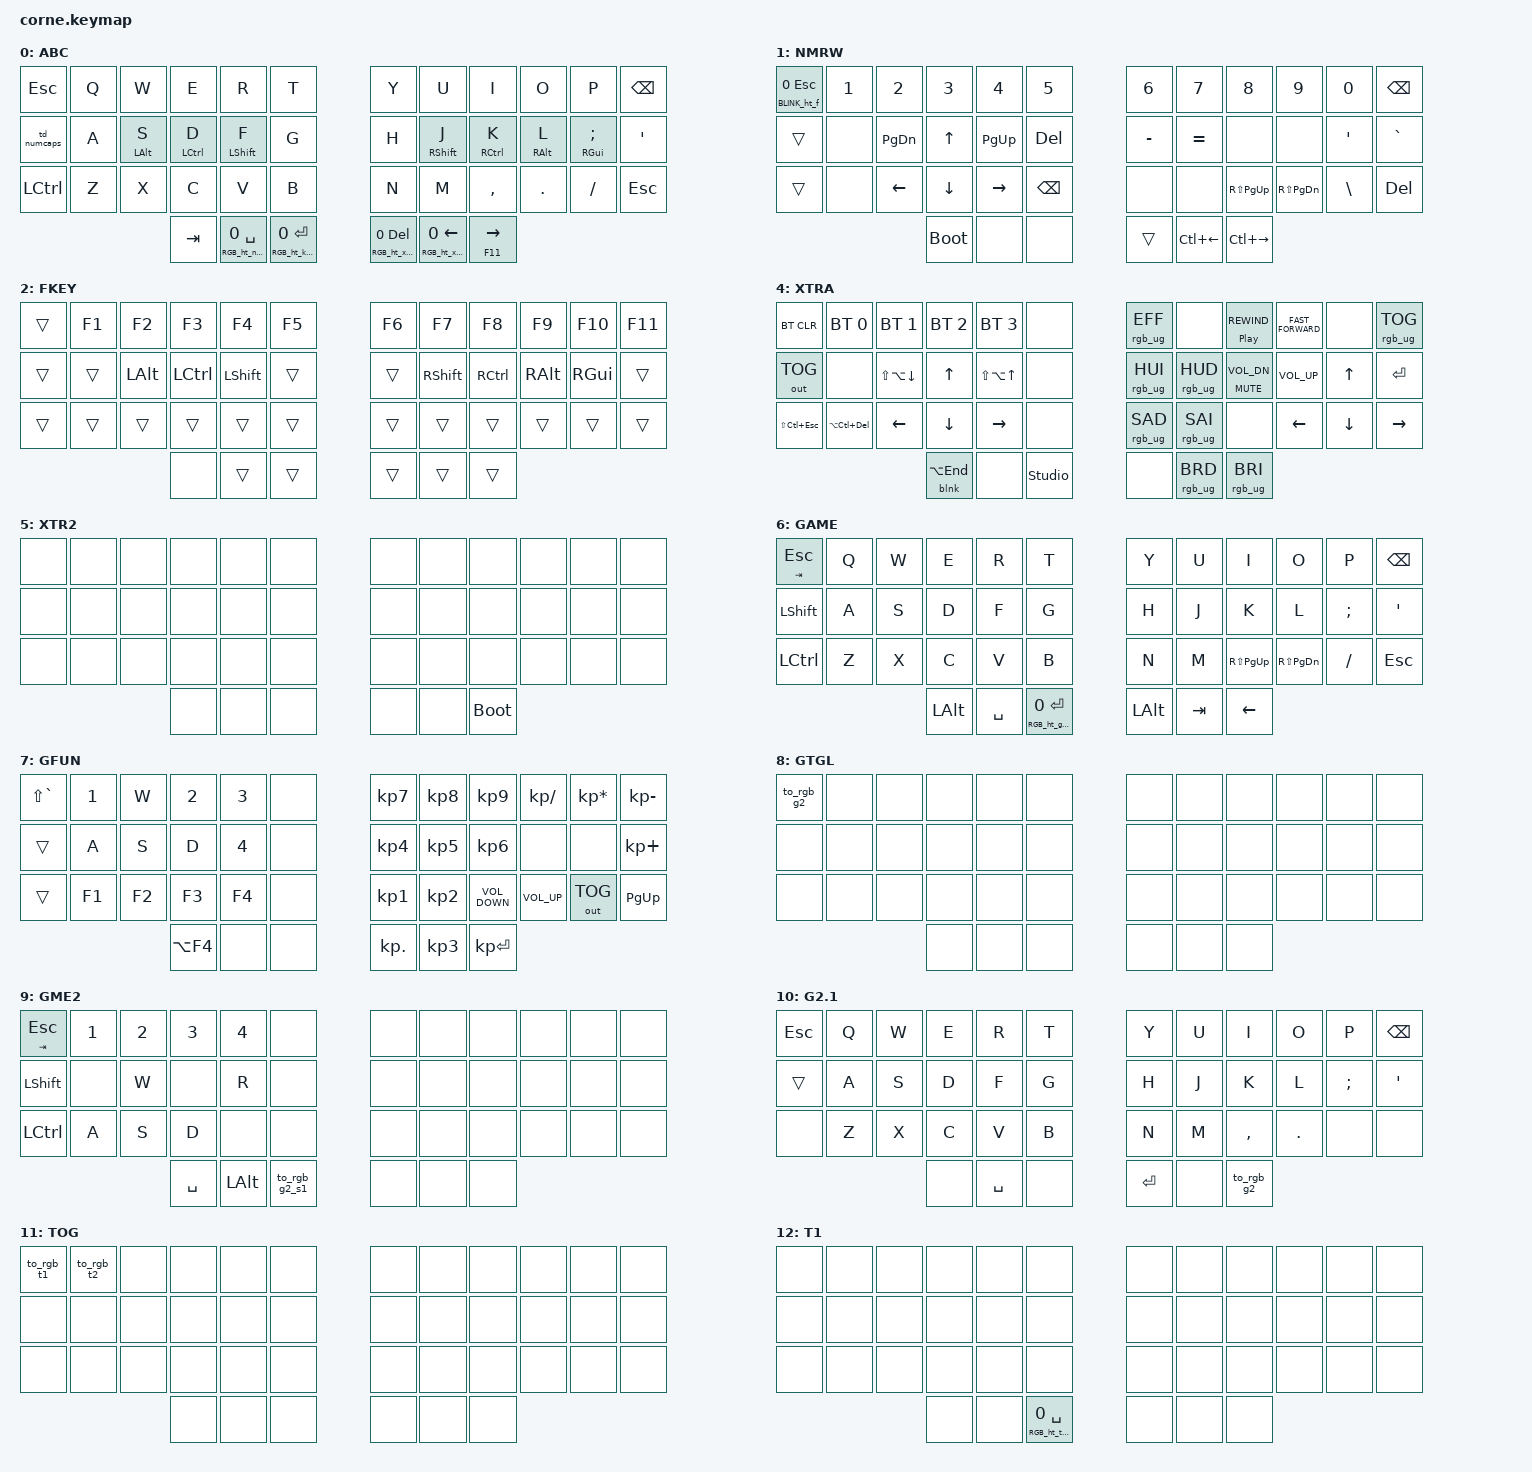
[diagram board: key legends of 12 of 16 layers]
/*
 * Copyright (c) 2020 The ZMK Contributors
 *
 * SPDX-License-Identifier: MIT
 */

#include <behaviors.dtsi>
#include <dt-bindings/zmk/bt.h>
#include <dt-bindings/zmk/keys.h>
#include <dt-bindings/zmk/outputs.h>
#include <dt-bindings/zmk/rgb.h>
#include "corne-rgb.dtsi"

/ {
    keymap {
        compatible = "zmk,keymap";

        abc_0 {
            display-name = "ABC";
            bindings = <
&kp ESC      &kp Q  &kp W           &kp E        &kp R                   &kp T                     &kp Y                 &kp U                   &kp I          &kp O            &kp P               &kp BSPC
&td_numcaps  &kp A  &hm LEFT_ALT S  &hm LCTRL D  &hm LEFT_SHIFT F        &kp G                     &kp H                 &hm RSHIFT J            &hm RCTRL K    &hm RIGHT_ALT L  &hm RGUI SEMICOLON  &kp SQT
&kp LCTRL    &kp Z  &kp X           &kp C        &kp V                   &kp B                     &kp N                 &kp M                   &kp COMMA      &kp DOT          &kp FSLH            &kp ESC
                                    &kp TAB      &RGB_ht_nmrw 0 SPACE    &RGB_ht_kpad 0 ENTER      &RGB_ht_xtra 0 DEL    &RGB_ht_xtra2 0 LEFT    &hm F11 RIGHT
            >;
        };

        nmrw_1 {
            display-name = "NMRW";
            bindings = <
&BLINK_ht_f 0 ESC    &kp N1  &kp N2         &kp N3       &kp N4       &kp N5         &kp N6     &kp N7        &kp N8         &kp N9         &kp N0    &kp BSPC
&trans               &none   &kp PAGE_DOWN  &kp UP       &kp PAGE_UP  &kp DEL        &kp MINUS  &kp EQUAL     &none          &none          &kp SQT   &kp GRAVE
&trans               &none   &kp LEFT       &kp DOWN     &kp RIGHT    &kp BACKSPACE  &none      &none         &kp RS(PG_UP)  &kp RS(PG_DN)  &kp BSLH  &kp DEL
                                            &bootloader  &none        &none          &trans     &kp LC(LEFT)  &kp LC(RIGHT)
            >;
        };

        FKEY_2 {
            display-name = "FKEY";
            bindings = <
&trans  &kp F1  &kp F2       &kp F3    &kp F4           &kp F5   &kp F6  &kp F7     &kp F8     &kp F9        &kp F10   &kp F11
&trans  &trans  &kp LEFT_ALT &kp LCTRL &kp LEFT_SHIFT   &trans   &trans  &kp RSHIFT &kp RCTRL  &kp RIGHT_ALT &kp RGUI  &trans
&trans  &trans  &trans       &trans    &trans           &trans   &trans  &trans     &trans     &trans        &trans    &trans
                             &none     &trans           &trans   &trans  &trans     &trans
            >;

            label = "FKEY";
        };

        k_pd_3 {
            display-name = "KPAD";
            bindings = <
&kp ESCAPE         &none      &kp F2            &none       &none              &kp F5           &kp KP_N7     &kp KP_N8  &kp KP_N9   &none     &none     &kp BSPC
&trans             &none      &kp HOME          &kp UP      &kp END            &kp DEL          &kp KP_N4     &kp KP_N5  &kp KP_N6   &none     &kp UP    &none
&hm (LC(X)) LC(C)  &kp LC(V)  &kp LC(LS(LEFT))  &kp DOWN    &kp LC(LS(RIGHT))  &kp BACKSPACE    &kp KP_N1     &kp KP_N2  &kp KP_N3   &kp LEFT  &kp DOWN  &kp RIGHT
                                                &kp LA(F4)  &none              &none            &kp KP_ENTER  &kp KP_N0  &kp KP_DOT
            >;
        };

        xtra_4 {
            display-name = "XTRA";
            bindings = <
&bt BT_CLR          &bt BT_SEL 0     &bt BT_SEL 1      &bt BT_SEL 2   &bt BT_SEL 3    &none             &rgb_ug RGB_EFF  &none            &hm C_PLAY_PAUSE C_REWIND  &kp C_FAST_FORWARD  &none     &rgb_ug RGB_TOG
&out OUT_TOG        &none            &kp LS(LA(DOWN))  &kp UP         &kp LS(LA(UP))  &none             &rgb_ug RGB_HUI  &rgb_ug RGB_HUD  &hm C_MUTE C_VOL_DN        &kp C_VOLUME_UP     &kp UP    &kp ENTER
&kp LS(LC(ESCAPE))  &kp LA(LC(DEL))  &kp LEFT          &kp DOWN       &kp RIGHT       &none             &rgb_ug RGB_SAD  &rgb_ug RGB_SAI  &none                      &kp LEFT            &kp DOWN  &kp RIGHT
                                                       &blnk LA(END)  &none           &studio_unlock    &none            &rgb_ug RGB_BRD  &rgb_ug RGB_BRI
            >;
        };

        xtr2_5 {
            display-name = "XTR2";
            bindings = <
&none  &none  &none  &none  &none  &none    &none  &none  &none        &none  &none  &none
&none  &none  &none  &none  &none  &none    &none  &none  &none        &none  &none  &none
&none  &none  &none  &none  &none  &none    &none  &none  &none        &none  &none  &none
                     &none  &none  &none    &none  &none  &bootloader
            >;

            label = "xtr2";
        };

        game_6 {
            display-name = "GAME";
            bindings = <
&hm TAB ESCAPE  &kp Q  &kp W  &kp E         &kp R      &kp T                   &kp Y     &kp U    &kp I            &kp O              &kp P     &kp BSPC
&kp LSHFT       &kp A  &kp S  &kp D         &kp F      &kp G                   &kp H     &kp J    &kp K            &kp L              &kp SEMI  &kp SQT
&kp LCTRL       &kp Z  &kp X  &kp C         &kp V      &kp B                   &kp N     &kp M    &kp RS(PAGE_UP)  &kp RS(PAGE_DOWN)  &kp FSLH  &kp ESC
                              &kp LEFT_ALT  &kp SPACE  &RGB_ht_gfun 0 ENTER    &kp LALT  &kp TAB  &kp LEFT
            >;
        };

        gfun_7 {
            display-name = "GFUN";
            bindings = <
&kp LS(GRAVE)   &kp N1  &kp W   &kp N2      &kp N3  &none    &kp KP_N7   &kp KP_N8  &kp KP_N9         &kp KP_DIVIDE            &kp KP_MULTIPLY  &kp KP_MINUS
&trans          &kp A   &kp S   &kp D       &kp N4  &none    &kp KP_N4   &kp KP_N5  &kp KP_N6         &none                    &none            &kp KP_PLUS
&trans          &kp F1  &kp F2  &kp F3      &kp F4  &none    &kp KP_N1   &kp KP_N2  &kp C_VOLUME_DOWN &kp C_VOLUME_UP          &out OUT_TOG     &kp PAGE_UP
                                &kp LA(F4)  &none   &none    &kp KP_DOT  &kp KP_N3  &kp KP_ENTER
            >;
        };

        game_toggle_8 {
            display-name = "GTGL";
            bindings = <
&to_rgb_g2  &none  &none  &none  &none  &none    &none  &none  &none  &none  &none  &none
&none       &none  &none  &none  &none  &none    &none  &none  &none  &none  &none  &none
&none       &none  &none  &none  &none  &none    &none  &none  &none  &none  &none  &none
                          &none  &none  &none    &none  &none  &none
            >;

            label = "GTGL";
        };

        game2_9 {
            display-name = "GME2";
            bindings = <
&hm TAB ESCAPE  &kp N1  &kp N2  &kp N3     &kp N4        &none            &none  &none  &none  &none  &none  &none
&kp LSHFT       &none   &kp W   &none      &kp R         &none            &none  &none  &none  &none  &none  &none
&kp LCTRL       &kp A   &kp S   &kp D      &none         &none            &none  &none  &none  &none  &none  &none
                                &kp SPACE  &kp LEFT_ALT  &to_rgb_g2_s1    &none  &none  &none
            >;

            label = "G2";
        };

        game2_sublayer1_10 {
            bindings = <
&kp ESC  &kp Q  &kp W  &kp E  &kp R      &kp T            &kp Y      &kp U  &kp I      &kp O    &kp P     &kp BSPC
&trans   &kp A  &kp S  &kp D  &kp F      &kp G            &kp H      &kp J  &kp K      &kp L    &kp SEMI  &kp APOS
&none    &kp Z  &kp X  &kp C  &kp V      &kp B            &kp N      &kp M  &kp COMMA  &kp DOT  &none     &none
                       &none  &kp SPACE  &none            &kp ENTER  &none  &to_rgb_g2
            >;

            label = "G2.1";
        };

        Toggle_Layers_11 {
            bindings = <
&to_rgb_t1  &to_rgb_t2  &none  &none  &none  &none    &none  &none  &none  &none  &none  &none
&none    &none       &none  &none  &none  &none    &none  &none  &none  &none  &none  &none
&none    &none       &none  &none  &none  &none    &none  &none  &none  &none  &none  &none
                            &none  &none  &none    &none  &none  &none
            >;

            label = "TOG";
        };

        toggle_1_12 {
            bindings = <
&none  &none  &none  &none  &none  &none                      &none  &none  &none  &none  &none  &none
&none  &none  &none  &none  &none  &none                      &none  &none  &none  &none  &none  &none
&none  &none  &none  &none  &none  &none                      &none  &none  &none  &none  &none  &none
                     &none  &none  &RGB_ht_t1_s1 0 SPACE    &none  &none  &none
            >;

            label = "T1";
        };

        toggle1_sublayer1_13 {
            bindings = <
&trans  &trans  &trans  &trans  &trans  &trans    &trans  &trans  &trans  &trans  &trans  &trans
&trans  &trans  &trans  &trans  &trans  &trans    &trans  &trans  &trans  &trans  &trans  &trans
&trans  &trans  &trans  &trans  &trans  &trans    &trans  &trans  &trans  &trans  &trans  &trans
                        &trans  &trans  &trans    &trans  &trans  &trans
            >;

            label = "T1.1";
        };

        toggle_2_14 {
            bindings = <
&none  &none  &none  &none  &none  &none                      &none  &none  &none  &none  &none  &none
&none  &none  &none  &none  &none  &none                      &none  &none  &none  &none  &none  &none
&none  &none  &none  &none  &none  &none                      &none  &none  &none  &none  &none  &none
                     &none  &none  &RGB_ht_t2_s1 0 SPACE    &none  &none  &none
            >;

            label = "T2";
        };

        toggle2_sublayer1_15 {
            bindings = <
&trans  &trans  &trans  &trans  &trans  &trans    &trans  &trans  &trans  &trans  &trans  &trans
&trans  &trans  &trans  &trans  &trans  &trans    &trans  &trans  &trans  &trans  &trans  &trans
&trans  &trans  &trans  &trans  &trans  &trans    &trans  &trans  &trans  &trans  &trans  &trans
                        &trans  &trans  &trans    &trans  &trans  &trans
            >;

            label = "T2.1";
        };

        extra1_16 { status = "reserved"; };

        extra2_17 { status = "reserved"; };

        extra3_18 { status = "reserved"; };

        extra4_19 { status = "reserved"; };
    };
};
